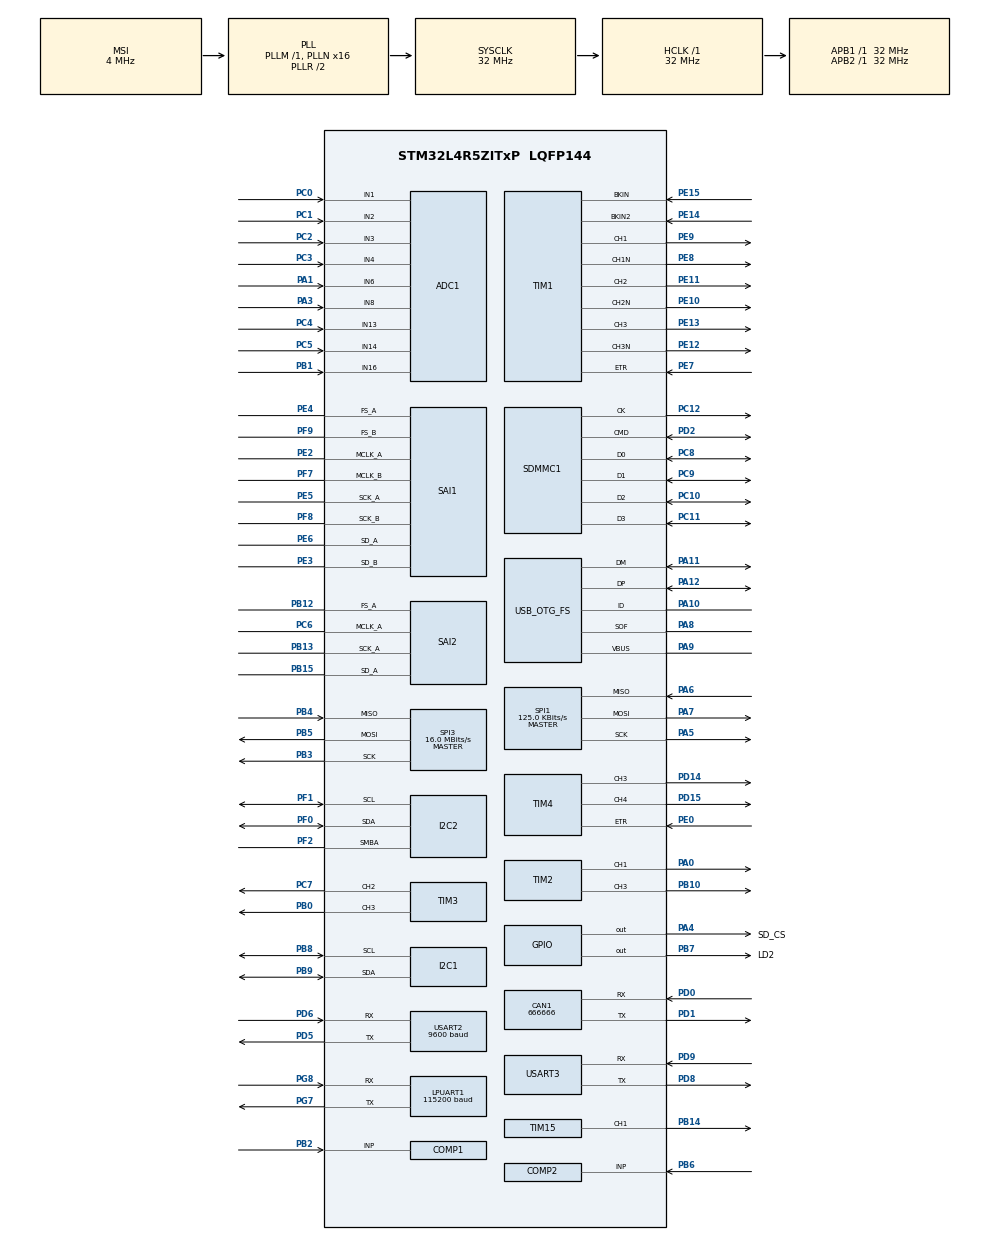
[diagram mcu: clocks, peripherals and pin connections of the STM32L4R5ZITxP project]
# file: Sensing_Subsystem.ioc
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ADC1.Channel-0\#ChannelRegularConversion=ADC_CHANNEL_1
ADC1.NbrOfConversionFlag=1
ADC1.OffsetNumber-0\#ChannelRegularConversion=ADC_OFFSET_NONE
ADC1.Rank-0\#ChannelRegularConversion=1
ADC1.SamplingTime-0\#ChannelRegularConversion=ADC_SAMPLETIME_2CYCLES_5
ADC1.master=1
CAN1.BS1=CAN_BS1_1TQ
CAN1.BS2=CAN_BS2_1TQ
CAN1.CalculateBaudRate=666666
CAN1.CalculateTimeBit=1500
CAN1.CalculateTimeQuantum=500.0
FATFS._USE_LFN=1
I2C1.Timing=0x00B07CB4
I2C2.Timeout=0x00008186
I2C2.Timing=0x00B07CB4
LPUART1.BaudRate=115200
LPUART1.WordLength=UART_WORDLENGTH_8B
Mcu.Family=STM32L4
Mcu.Name=STM32L4R5ZITxP
Mcu.Package=LQFP144
NVIC.LPUART1_IRQn=true\:0\:0\:false\:false\:true\:true\:true\:true
NVIC.PriorityGroup=NVIC_PRIORITYGROUP_4
NVIC.USART2_IRQn=true\:0\:0\:false\:false\:true\:true\:true\:true
PA0.Signal=S_TIM2_CH1
PA1.Signal=ADCx_IN6
PA10.Mode=OTG/Dual_Role_Device
PA10.Signal=USB_OTG_FS_ID
PA11.Mode=OTG/Dual_Role_Device
PA11.Signal=USB_OTG_FS_DM
PA12.Mode=OTG/Dual_Role_Device
PA12.Signal=USB_OTG_FS_DP
PA13\ (JTMS/SWDIO).Mode=Serial_Wire
PA13\ (JTMS/SWDIO).Signal=SYS_JTMS-SWDIO
PA14\ (JTCK/SWCLK).Mode=Serial_Wire
PA14\ (JTCK/SWCLK).Signal=SYS_JTCK-SWCLK
PA3.Signal=ADCx_IN8
PA4.GPIO_Label=SD_CS
PA4.GPIO_Speed=GPIO_SPEED_FREQ_VERY_HIGH
PA4.PinState=GPIO_PIN_SET
PA4.Signal=GPIO_Output
PA5.Mode=Full_Duplex_Master
PA5.Signal=SPI1_SCK
PA6.Mode=Full_Duplex_Master
PA6.Signal=SPI1_MISO
PA7.Mode=Full_Duplex_Master
PA7.Signal=SPI1_MOSI
PA8.Mode=Activate_SOF_FS
PA8.Signal=USB_OTG_FS_SOF
PA9.Mode=Activate_VBUS
PA9.Signal=USB_OTG_FS_VBUS
PB0.Signal=S_TIM3_CH3
PB1.Signal=ADCx_IN16
PB10.Signal=S_TIM2_CH3
PB12.Mode=SAI_A_MasterWithClock
PB12.Signal=SAI2_FS_A
PB13.Mode=SAI_A_MasterWithClock
PB13.Signal=SAI2_SCK_A
PB14.Signal=S_TIM15_CH1
PB15.Mode=SAI_A_MasterWithClock
PB15.Signal=SAI2_SD_A
PB2.Mode=INP
PB2.Signal=COMP1_INP
PB3\ (JTDO/TRACESWO).Mode=Full_Duplex_Master
PB3\ (JTDO/TRACESWO).Signal=SPI3_SCK
PB4\ (NJTRST).Mode=Full_Duplex_Master
PB4\ (NJTRST).Signal=SPI3_MISO
PB5.Mode=Full_Duplex_Master
PB5.Signal=SPI3_MOSI
PB6.Mode=INP
PB6.Signal=COMP2_INP
PB7.GPIO_Label=LD2
PB7.Signal=GPIO_Output
PB8.GPIO_Pu=GPIO_PULLUP
PB8.Mode=I2C
PB8.Signal=I2C1_SCL
PB9.GPIO_Pu=GPIO_PULLUP
PB9.Mode=I2C
PB9.Signal=I2C1_SDA
PC0.Signal=ADCx_IN1
PC1.Signal=ADCx_IN2
PC10.Mode=SD_4_bits_Wide_bus
PC10.Signal=SDMMC1_D2
PC11.Mode=SD_4_bits_Wide_bus
PC11.Signal=SDMMC1_D3
PC12.Mode=SD_4_bits_Wide_bus
PC12.Signal=SDMMC1_CK
PC13.Mode=SYS_WakeUp1
PC13.Signal=SYS_WKUP2
PC14-OSC32_IN\ (PC14).Mode=LSE-External-Oscillator
PC14-OSC32_IN\ (PC14).Signal=RCC_OSC32_IN
PC15-OSC32_OUT\ (PC15).Mode=LSE-External-Oscillator
PC15-OSC32_OUT\ (PC15).Signal=RCC_OSC32_OUT
PC2.Signal=ADCx_IN3
PC3.Signal=ADCx_IN4
PC4.Signal=ADCx_IN13
PC5.Signal=ADCx_IN14
PC6.Mode=SAI_A_MasterWithClock
PC6.Signal=SAI2_MCLK_A
PC7.Signal=S_TIM3_CH2
PC8.Mode=SD_4_bits_Wide_bus
PC8.Signal=SDMMC1_D0
PC9.Mode=SD_4_bits_Wide_bus
PC9.Signal=SDMMC1_D1
PD0.Mode=CAN_Activate
PD0.Signal=CAN1_RX
PD1.Mode=CAN_Activate
PD1.Signal=CAN1_TX
PD14.Signal=S_TIM4_CH3
PD15.Signal=S_TIM4_CH4
PD2.Mode=SD_4_bits_Wide_bus
PD2.Signal=SDMMC1_CMD
PD3.Signal=USART2_CTS
PD4.Signal=USART2_RTS
PD5.Mode=Asynchronous
PD5.Signal=USART2_TX
PD6.Mode=Asynchronous
PD6.Signal=USART2_RX
PD8.Mode=Asynchronous
PD8.Signal=USART3_TX
PD9.Mode=Asynchronous
PD9.Signal=USART3_RX
PE0.Signal=S_TIM4_ETR
PE10.Mode=PWM Generation2 CH2 CH2N
PE10.Signal=TIM1_CH2N
PE11.Signal=S_TIM1_CH2
PE12.Mode=PWM Generation3 CH3 CH3N
PE12.Signal=TIM1_CH3N
PE13.Signal=S_TIM1_CH3
PE14.Mode=Activate-Break-Input-2
PE14.Signal=TIM1_BKIN2
PE15.Mode=Activate-Break-Input
PE15.Signal=TIM1_BKIN
PE2.Mode=SAI_A_MasterWithClock
PE2.Signal=SAI1_MCLK_A
PE3.Mode=SAI_B_MasterWithClock
PE3.Signal=SAI1_SD_B
PE4.Mode=SAI_A_MasterWithClock
PE4.Signal=SAI1_FS_A
PE5.Mode=SAI_A_MasterWithClock
PE5.Signal=SAI1_SCK_A
PE6.Mode=SAI_A_MasterWithClock
PE6.Signal=SAI1_SD_A
PE7.Signal=S_TIM1_ETR
PE8.Mode=PWM Generation1 CH1 CH1N
PE8.Signal=TIM1_CH1N
PE9.Signal=S_TIM1_CH1
PF0.GPIO_Pu=GPIO_PULLUP
PF0.Mode=SMBus-Alert-mode
PF0.Signal=I2C2_SDA
PF1.GPIO_Pu=GPIO_PULLUP
PF1.Mode=SMBus-Alert-mode
PF1.Signal=I2C2_SCL
PF2.GPIO_Pu=GPIO_PULLUP
PF2.Mode=SMBus-Alert-mode
PF2.Signal=I2C2_SMBA
PF7.Mode=SAI_B_MasterWithClock
PF7.Signal=SAI1_MCLK_B
PF8.Mode=SAI_B_MasterWithClock
PF8.Signal=SAI1_SCK_B
PF9.Mode=SAI_B_MasterWithClock
PF9.Signal=SAI1_FS_B
PG7.Mode=Asynchronous
PG7.Signal=LPUART1_TX
PG8.Mode=Asynchronous
PG8.Signal=LPUART1_RX
PH0-OSC_IN\ (PH0).Mode=HSE-External-Oscillator
PH0-OSC_IN\ (PH0).Signal=RCC_OSC_IN
PH1-OSC_OUT\ (PH1).Mode=HSE-External-Oscillator
PH1-OSC_OUT\ (PH1).Signal=RCC_OSC_OUT
ProjectManager.HeapSize=0x200
ProjectManager.StackSize=0x400
ProjectManager.TargetToolchain=STM32CubeIDE
RCC.ADCFreq_Value=48000000
RCC.AHBFreq_Value=32000000
RCC.APB1Freq_Value=32000000
RCC.APB1TimFreq_Value=32000000
RCC.APB2Freq_Value=32000000
RCC.APB2TimFreq_Value=32000000
RCC.CortexFreq_Value=32000000
RCC.HCLKFreq_Value=32000000
RCC.HSE_VALUE=8000000
RCC.HSI48_VALUE=48000000
RCC.HSI_VALUE=16000000
RCC.MSI_VALUE=4000000
RCC.PLLN=16
RCC.PLLSAI1N=24
RCC.SYSCLKFreq_VALUE=32000000
RCC.SYSCLKSource=RCC_SYSCLKSOURCE_PLLCLK
RCC.USBFreq_Value=48000000
RCC.VCOOutputFreq_Value=64000000
SAI1.InitProtocol-SAI_A_MasterWithClock=Enable
SAI1.Instance-SAI_A_MasterWithClock=SAI$Index_Block_A
SAI1.Instance-SAI_B_MasterWithClock=SAI$Index_Block_B
SAI1.MClockEnable-SAI_A_MasterWithClock=SAI_MASTERCLOCK_ENABLE
SAI1.MClockEnable-SAI_B_MasterWithClock=SAI_MASTERCLOCK_ENABLE
SAI1.Synchro-SAI_A_MasterWithClock=SAI_ASYNCHRONOUS
SAI1.Synchro-SAI_B_MasterWithClock=SAI_ASYNCHRONOUS
SAI1.VirtualMode-SAI_A_MasterWithClock=VM_MASTER
SAI1.VirtualMode-SAI_B_MasterWithClock=VM_MASTER
SAI1.VirtualProtocol-SAI_A_BASIC=VM_BASIC_PROTOCOL
SAI2.Instance-SAI_A_MasterWithClock=SAI$Index_Block_A
SAI2.MClockEnable-SAI_A_MasterWithClock=SAI_MASTERCLOCK_ENABLE
SAI2.Synchro-SAI_A_MasterWithClock=SAI_ASYNCHRONOUS
SAI2.VirtualMode-SAI_A_MasterWithClock=VM_MASTER
SH.ADCx_IN1.0=ADC1_IN1,IN1-Single-Ended
SH.ADCx_IN13.0=ADC1_IN13,IN13-Single-Ended
SH.ADCx_IN14.0=ADC1_IN14,IN14-Single-Ended
SH.ADCx_IN16.0=ADC1_IN16,IN16-Single-Ended
SH.ADCx_IN2.0=ADC1_IN2,IN2-Single-Ended
SH.ADCx_IN3.0=ADC1_IN3,IN3-Single-Ended
SH.ADCx_IN4.0=ADC1_IN4,IN4-Single-Ended
SH.ADCx_IN6.0=ADC1_IN6,IN6-Single-Ended
SH.ADCx_IN8.0=ADC1_IN8,IN8-Single-Ended
SH.S_TIM15_CH1.0=TIM15_CH1,PWM Generation1 CH1
SH.S_TIM1_CH1.0=TIM1_CH1,PWM Generation1 CH1 CH1N
SH.S_TIM1_CH2.0=TIM1_CH2,PWM Generation2 CH2 CH2N
SH.S_TIM1_CH3.0=TIM1_CH3,PWM Generation3 CH3 CH3N
SH.S_TIM1_ETR.0=TIM1_ETR,ETR-as-clearing-source
SH.S_TIM2_CH1.0=TIM2_CH1,PWM Generation1 CH1
SH.S_TIM2_CH3.0=TIM2_CH3,PWM Generation3 CH3
SH.S_TIM3_CH2.0=TIM3_CH2,PWM Generation2 CH2
SH.S_TIM3_CH3.0=TIM3_CH3,PWM Generation3 CH3
SH.S_TIM4_CH3.0=TIM4_CH3,PWM Generation3 CH3
SH.S_TIM4_CH4.0=TIM4_CH4,PWM Generation4 CH4
SH.S_TIM4_ETR.0=TIM4_ETR,ETR-as-clearing-source
SPI1.BaudRatePrescaler=SPI_BAUDRATEPRESCALER_256
SPI1.CalculateBaudRate=125.0 KBits/s
SPI1.DataSize=SPI_DATASIZE_8BIT
SPI1.Direction=SPI_DIRECTION_2LINES
SPI1.Mode=SPI_MODE_MASTER
SPI1.VirtualType=VM_MASTER
SPI3.CalculateBaudRate=16.0 MBits/s
SPI3.Direction=SPI_DIRECTION_2LINES
SPI3.Mode=SPI_MODE_MASTER
SPI3.VirtualType=VM_MASTER
TIM1.Channel-PWM\ Generation1\ CH1\ CH1N=TIM_CHANNEL_1
TIM1.Channel-PWM\ Generation2\ CH2\ CH2N=TIM_CHANNEL_2
TIM1.Channel-PWM\ Generation3\ CH3\ CH3N=TIM_CHANNEL_3
TIM15.Channel-PWM\ Generation1\ CH1=TIM_CHANNEL_1
TIM2.Channel-PWM\ Generation1\ CH1=TIM_CHANNEL_1
TIM2.Channel-PWM\ Generation3\ CH3=TIM_CHANNEL_3
TIM3.Channel-PWM\ Generation2\ CH2=TIM_CHANNEL_2
TIM3.Channel-PWM\ Generation3\ CH3=TIM_CHANNEL_3
TIM4.Channel-PWM\ Generation3\ CH3=TIM_CHANNEL_3
TIM4.Channel-PWM\ Generation4\ CH4=TIM_CHANNEL_4
USART2.BaudRate=9600
USART2.VirtualMode-Asynchronous=VM_ASYNC
USART3.VirtualMode-Asynchronous=VM_ASYNC
VP_COMP1_VS_VREFINT.Mode=VREFINT
VP_FATFS_VS_Generic.Mode=User_defined
VP_SAI1_VP_$IpInstance_SAIA_SAI_BASIC.Mode=SAI_A_BASIC
board=NUCLEO-L4R5ZI-P

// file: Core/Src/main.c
/* USER CODE BEGIN Header */
/**
  ******************************************************************************
  * @file          : main.c
  * @brief         : Main program body - IMU + GPS + SD Card Integration
  * PROJECT        : EEE4113F Group 23 — Wave Direction, 2026
  * Author         : Batsirai Chris Rwatirera
  * BOARD          : STM32 NUCLEO-L4R5ZI-P
  ******************************************************************************
  */
/* USER CODE END Header */
#include "main.h"
#include "adc.h"
#include "can.h"
#include "comp.h"
#include "fatfs.h"
#include "i2c.h"
#include "usart.h"
#include "sai.h"
#include "sdmmc.h"
#include "spi.h"
#include "tim.h"
#include "usb_otg.h"
#include "gpio.h"

/* USER CODE BEGIN Includes */
#include <string.h>
#include <stdio.h>
#include "imu.h"
#include "gps.h"
#include "storage.h"  /* �? NEW: SD card module */
/* USER CODE END Includes */

/* USER CODE BEGIN PV */
extern UART_HandleTypeDef hlpuart1;
extern UART_HandleTypeDef huart2;
extern I2C_HandleTypeDef hi2c1;
/* USER CODE END PV */

void SystemClock_Config(void);
void PeriphCommonClock_Config(void);

/* USER CODE BEGIN 0 */

/* ═══════════════════════════════════════════════════════════════════════════
 * SD CARD SPI FUNCTIONS
 * ═══════════════════════════════════════════════════════════════════════════
 */

static uint8_t sd_spi_txrx(uint8_t data)
{
    uint8_t rx = 0xFF;
    HAL_SPI_TransmitReceive(&hspi1, &data, &rx, 1, HAL_MAX_DELAY);
    return rx;
}

static void sd_cs_high(void)
{
    HAL_GPIO_WritePin(GPIOA, GPIO_PIN_4, GPIO_PIN_SET);  // CS = PA4
    sd_spi_txrx(0xFF);
}

static void sd_cs_low(void)
{
    HAL_GPIO_WritePin(GPIOA, GPIO_PIN_4, GPIO_PIN_RESET);  // CS = PA4
    sd_spi_txrx(0xFF);
}

static void sd_send_dummy_clocks(void)
{
    sd_cs_high();
    for (int i = 0; i < 10; i++) {
        sd_spi_txrx(0xFF);
    }
}

static uint8_t sd_send_cmd(uint8_t cmd, uint32_t arg, uint8_t crc)
{
    uint8_t r1;

    sd_cs_low();

    sd_spi_txrx(0x40 | cmd);
    sd_spi_txrx((uint8_t)(arg >> 24));
    sd_spi_txrx((uint8_t)(arg >> 16));
    sd_spi_txrx((uint8_t)(arg >> 8));
    sd_spi_txrx((uint8_t)(arg));
    sd_spi_txrx(crc);

    for (int i = 0; i < 10; i++) {
        r1 = sd_spi_txrx(0xFF);
        if ((r1 & 0x80) == 0) {
            return r1;
        }
    }

    return 0xFF;
}

uint8_t sd_init(void)
{
    uint8_t r1;
    uint8_t r7[4];

    sd_send_dummy_clocks();

    r1 = sd_send_cmd(0, 0x00000000, 0x95);
    sd_cs_high();
    if (r1 != 0x01) return 1;

    r1 = sd_send_cmd(8, 0x000001AA, 0x87);
    r7[0] = sd_spi_txrx(0xFF);
    r7[1] = sd_spi_txrx(0xFF);
    r7[2] = sd_spi_txrx(0xFF);
    r7[3] = sd_spi_txrx(0xFF);
    sd_cs_high();

    if (r1 != 0x01 || r7[2] != 0x01 || r7[3] != 0xAA) return 2;

    uint32_t timeout = 0;
    do {
        r1 = sd_send_cmd(55, 0x00000000, 0xFF);
        sd_cs_high();
        r1 = sd_send_cmd(41, 0x40000000, 0xFF);
        sd_cs_high();
        timeout++;
        HAL_Delay(10);
    } while ((r1 != 0x00) && (timeout < 500));

    if (r1 != 0x00) return 3;

    r1 = sd_send_cmd(58, 0x00000000, 0xFF);
    sd_spi_txrx(0xFF);
    sd_spi_txrx(0xFF);
    sd_spi_txrx(0xFF);
    sd_spi_txrx(0xFF);
    sd_cs_high();

    if (r1 != 0x00) return 4;

    return 0;
}

uint8_t sd_read_block(uint32_t block_addr, uint8_t *buffer)
{
    uint8_t r1;
    uint8_t token;

    r1 = sd_send_cmd(17, block_addr, 0xFF);
    if (r1 != 0x00) {
        sd_cs_high();
        return r1;
    }

    for (uint32_t i = 0; i < 100000; i++) {
        token = sd_spi_txrx(0xFF);
        if (token == 0xFE) break;
    }

    if (token != 0xFE) {
        sd_cs_high();
        return 0xFE;
    }

    for (uint32_t i = 0; i < 512; i++) {
        buffer[i] = sd_spi_txrx(0xFF);
    }

    sd_spi_txrx(0xFF);
    sd_spi_txrx(0xFF);

    sd_cs_high();
    return 0x00;
}

uint8_t sd_write_block(uint32_t block_addr, const uint8_t *data)
{
    uint8_t r1;
    uint8_t resp;
    uint8_t dummy;

    r1 = sd_send_cmd(24, block_addr, 0xFF);
    if (r1 != 0x00) {
        sd_cs_high();
        return r1;
    }

    sd_spi_txrx(0xFF);
    sd_spi_txrx(0xFE);

    for (uint32_t i = 0; i < 512; i++) {
        sd_spi_txrx(data[i]);
    }

    sd_spi_txrx(0xFF);
    sd_spi_txrx(0xFF);

    resp = sd_spi_txrx(0xFF);

    if ((resp & 0x1F) != 0x05) {
        sd_cs_high();
        return resp;
    }

    uint32_t timeout = 1000000;
    do {
        dummy = sd_spi_txrx(0xFF);
        timeout--;
    } while ((dummy != 0xFF) && (timeout > 0));

    sd_cs_high();

    return (timeout == 0) ? 0xFE : 0x00;
}

/* USER CODE END 0 */

int main(void)
{

  /* USER CODE BEGIN 1 */
  /* Enable FPU before HAL_Init() */
  SCB->CPACR |= ((3UL << 10*2)|(3UL << 11*2));
  /* USER CODE END 1 */

  /* MCU Configuration--------------------------------------------------------*/

  /* Reset of all peripherals, Initializes the Flash interface and the Systick. */
  HAL_Init();

  /* USER CODE BEGIN Init */

  // LED setup via direct register access
  RCC->AHB2ENR |= RCC_AHB2ENR_GPIOBEN;  // Enable GPIOB clock
  RCC->AHB2ENR |= RCC_AHB2ENR_GPIOCEN;  // Enable GPIOC clock

  // Configure PB7 (Blue LED), PB14 (Red LED) as outputs
  GPIOB->MODER &= ~(3UL << (7*2));
  GPIOB->MODER |= (1UL << (7*2));
  GPIOB->MODER &= ~(3UL << (14*2));
  GPIOB->MODER |= (1UL << (14*2));

  // Configure PC7 (Green LED) as output
  GPIOC->MODER &= ~(3UL << (7*2));
  GPIOC->MODER |= (1UL << (7*2));

  /* USER CODE END Init */

  /* Configure the system clock */
  SystemClock_Config();

  /* Configure the peripherals common clocks */
  PeriphCommonClock_Config();

  /* USER CODE BEGIN SysInit */

    // Initialize peripherals
    MX_GPIO_Init();
    MX_LPUART1_UART_Init();
    MX_USART2_UART_Init();
    MX_I2C1_Init();
    MX_SPI1_Init();       /* �? NEW: SPI for SD card */
    MX_FATFS_Init();      /* �? NEW: FatFs middleware */

    // Helper function to print messages
    void print_msg(const char* msg) {
      HAL_UART_Transmit(&hlpuart1, (uint8_t*)msg, strlen(msg), 1000);
    }

    // Print startup banner
    print_msg("\r\n========================================\r\n");
    print_msg("  EEE4113F Group 23 — Wave Direction\r\n");
    print_msg("  IMU + GPS + SD Card Integration\r\n");
    print_msg("=========================================\r\n");

    char cfg[300];
    snprintf(cfg, sizeof(cfg),
        "  IMU rate    : %d Hz\r\n"
        "  GPS rate    : %d Hz\r\n"
        "  Session     : %d min  (%lu IMU samples)\r\n"
        "  Interval    : %d hours\r\n"
        "  IMU batch   : every %d samples (1s)\r\n"
        "  GPS batch   : every %d samples (10s)\r\n"
        "  SD card     : SPI mode, power-loss safe\r\n"
        "=========================================\r\n",
        IMU_SAMPLE_RATE_HZ,
        GPS_SAMPLE_RATE_HZ,
        IMU_SESSION_DURATION_MIN,
        (unsigned long)IMU_SAMPLES_PER_SESSION,
        IMU_SESSION_INTERVAL_HOURS,
        IMU_BATCH_SIZE,
        GPS_BATCH_SIZE);
    print_msg(cfg);

    /* ── ONE-TIME STARTUP INITIALISATION ───────────────────────────────── */

    // Initialize IMU module
    print_msg("[MAIN] Initialising IMU...\r\n");
    if (!IMU_Init())
    {
        print_msg("[MAIN] IMU init FAILED. Halting.\r\n");
        while(1) {
          GPIOB->BSRR = GPIO_PIN_14;  // Red LED blink = error
          HAL_Delay(200);
          GPIOB->BSRR = GPIO_PIN_14 << 16;
          HAL_Delay(200);
        }
    }

    // Calibrate IMU (sensor must be still and flat for 5 seconds)
    print_msg("[MAIN] Calibrating IMU (5 sec - keep still)...\r\n");
    if (!IMU_Calibrate())
    {
        print_msg("[MAIN] IMU calibration FAILED. Halting.\r\n");
        while(1) {
          GPIOB->BSRR = GPIO_PIN_14;  // Red LED blink = error
          HAL_Delay(200);
          GPIOB->BSRR = GPIO_PIN_14 << 16;
          HAL_Delay(200);
        }
    }

    // Initialize GPS module
    print_msg("[MAIN] Initialising GPS...\r\n");
    if (!GPS_Init())
    {
        print_msg("[MAIN] GPS init FAILED. Continuing without GPS.\r\n");
        /* Note: GPS hardware issue known - continue with IMU-only logging */
    }

    // ★ NEW: Initialize SD card ★
    print_msg("[MAIN] Initialising SD card...\r\n");
    if (!Storage_Init())
    {
        print_msg("[MAIN] SD card init FAILED. Halting.\r\n");
        print_msg("[MAIN] Check: Card inserted? FAT32 formatted? SPI wiring?\r\n");
        while(1) {
          GPIOB->BSRR = GPIO_PIN_14;  // Red LED blink = error
          HAL_Delay(300);
          GPIOB->BSRR = GPIO_PIN_14 << 16;
          HAL_Delay(300);
        }
    }

    print_msg("[MAIN] All modules ready. Starting session loop.\r\n\r\n");

    GPIOC->BSRR = GPIO_PIN_7;  // Green LED ON = initialization complete

    /* ── DAILY SESSION LOOP ──────────────────────────────────────────── */

    uint16_t session_number = 0;

    while(1)
    {
      /* ── START SESSION ───────────────────────────────────────────────── */
      session_number++;
      char sess_msg[120];
      snprintf(sess_msg, sizeof(sess_msg),
          "[MAIN] Session %u starting (30 min: IMU @ %d Hz, GPS @ %d Hz)\r\n",
          session_number, IMU_SAMPLE_RATE_HZ, GPS_SAMPLE_RATE_HZ);
      print_msg(sess_msg);

      IMU_Wake();
      GPS_Wake();

      // ★ NEW: Open session files on SD card ★
      if (!Storage_OpenSession(session_number))
      {
          print_msg("[MAIN] ERROR: Could not open SD session. Halting.\r\n");
          while(1) {
            GPIOB->BSRR = GPIO_PIN_14;  // Red LED blink = error
            HAL_Delay(500);
            GPIOB->BSRR = GPIO_PIN_14 << 16;
            HAL_Delay(500);
          }
      }

      /* ── RECORD FOR 30 MINUTES ──────────────────────────────────────── */
      uint32_t session_start = HAL_GetTick();
      uint32_t imu_samples_written = 0;
      uint32_t gps_samples_written = 0;

      while (HAL_GetTick() - session_start < IMU_SESSION_MS)
      {
          GPIOB->BSRR = GPIO_PIN_7;  // Blue LED ON during sampling

          // Non-blocking ticks for both sensors
          IMU_Tick();
          GPS_Tick();

          // ★ Check if IMU batch is ready (every 100 samples = 1 second) ★
          if (imu_batch_ready)
          {
              // Write to SD card (includes f_sync for power-loss safety)
              if (!Storage_WriteIMUBatch(imu_batch, imu_batch_count))
              {
                  print_msg("[MAIN] ERROR: IMU write failed!\r\n");
                  /* Could halt here, or continue logging */
              }

              imu_samples_written += imu_batch_count;
              IMU_ClearBatch();

              GPIOB->BSRR = GPIO_PIN_7 << 16;  // Blue LED OFF after write
          }

          // ★ Check if GPS batch is ready (every 80 samples = 10 seconds) ★
          if (gps_batch_ready)
          {
              // Write to SD card (includes f_sync for power-loss safety)
              if (!Storage_WriteGPSBatch(gps_batch, gps_batch_count))
              {
                  print_msg("[MAIN] ERROR: GPS write failed!\r\n");
                  /* Could halt here, or continue logging */
              }

              gps_samples_written += gps_batch_count;
              GPS_ClearBatch();
          }
      }

      /* ── END SESSION ──────────────────────────────────────────────────── */
      char end_msg[120];
      snprintf(end_msg, sizeof(end_msg),
          "[MAIN] Session %u complete.\r\n"
          "       IMU: %lu samples | GPS: %lu samples\r\n",
          session_number,
          (unsigned long)imu_samples_written,
          (unsigned long)gps_samples_written);
      print_msg(end_msg);

      IMU_Sleep();
      GPS_Sleep();

      // ★ NEW: Close session files (final sync happens here) ★
      Storage_CloseSession();

      /* ── WAIT 23.5 HOURS UNTIL NEXT SESSION ────────────────────────── */
      uint32_t elapsed = HAL_GetTick() - session_start;
      uint32_t wait_time = 0;

      if (IMU_SESSION_INTERVAL_MS > elapsed)
      {
          wait_time = IMU_SESSION_INTERVAL_MS - elapsed;
      }

      char wait_msg[70];
      snprintf(wait_msg, sizeof(wait_msg),
          "[MAIN] Sleeping for %.1f hours until next session.\r\n\r\n",
          (float)wait_time / 3600000.0f);
      print_msg(wait_msg);

      HAL_Delay(wait_time);  // Wait remainder of 24 hours
    }

  /* USER CODE END SysInit */

  /* Initialize all configured peripherals */
  MX_GPIO_Init();
  MX_ADC1_Init();
  MX_CAN1_Init();
  MX_COMP1_Init();
  MX_COMP2_Init();
  MX_I2C1_Init();
  MX_I2C2_SMBUS_Init();
  MX_LPUART1_UART_Init();
  MX_USART2_UART_Init();
  MX_USART3_UART_Init();
  MX_SAI1_Init();
  MX_SAI2_Init();
  MX_SDMMC1_SD_Init();
  MX_SPI1_Init();
  MX_SPI3_Init();
  MX_TIM1_Init();
  MX_TIM2_Init();
  MX_TIM3_Init();
  MX_TIM4_Init();
  MX_TIM15_Init();
  MX_USB_OTG_FS_USB_Init();
  MX_FATFS_Init();
  /* USER CODE BEGIN 2 */

  // This code never runs because we're stuck in the while(1) above

  /* USER CODE END 2 */

  /* Infinite loop */
  while (1)
  {

  }
}

void SystemClock_Config(void)
{
  RCC_OscInitTypeDef RCC_OscInitStruct = {0};
  RCC_ClkInitTypeDef RCC_ClkInitStruct = {0};

  /** Configure the main internal regulator output voltage
  */
  if (HAL_PWREx_ControlVoltageScaling(PWR_REGULATOR_VOLTAGE_SCALE1) != HAL_OK)
  {
    Error_Handler();
  }

  /** Configure LSE Drive Capability
  */
  HAL_PWR_EnableBkUpAccess();
  __HAL_RCC_LSEDRIVE_CONFIG(RCC_LSEDRIVE_LOW);

  /** Initializes the RCC Oscillators according to the specified parameters
  * in the RCC_OscInitTypeDef structure.
  */
  RCC_OscInitStruct.OscillatorType = RCC_OSCILLATORTYPE_LSE|RCC_OSCILLATORTYPE_MSI;
  RCC_OscInitStruct.LSEState = RCC_LSE_ON;
  RCC_OscInitStruct.MSIState = RCC_MSI_ON;
  RCC_OscInitStruct.MSICalibrationValue = 0;
  RCC_OscInitStruct.MSIClockRange = RCC_MSIRANGE_6;
  RCC_OscInitStruct.PLL.PLLState = RCC_PLL_ON;
  RCC_OscInitStruct.PLL.PLLSource = RCC_PLLSOURCE_MSI;
  RCC_OscInitStruct.PLL.PLLM = 1;
  RCC_OscInitStruct.PLL.PLLN = 16;
  RCC_OscInitStruct.PLL.PLLP = RCC_PLLP_DIV2;
  RCC_OscInitStruct.PLL.PLLQ = RCC_PLLQ_DIV2;
  RCC_OscInitStruct.PLL.PLLR = RCC_PLLR_DIV2;
  if (HAL_RCC_OscConfig(&RCC_OscInitStruct) != HAL_OK)
  {
    Error_Handler();
  }

  /** Initializes the CPU, AHB and APB buses clocks
  */
  RCC_ClkInitStruct.ClockType = RCC_CLOCKTYPE_HCLK|RCC_CLOCKTYPE_SYSCLK
                              |RCC_CLOCKTYPE_PCLK1|RCC_CLOCKTYPE_PCLK2;
  RCC_ClkInitStruct.SYSCLKSource = RCC_SYSCLKSOURCE_PLLCLK;
  RCC_ClkInitStruct.AHBCLKDivider = RCC_SYSCLK_DIV1;
  RCC_ClkInitStruct.APB1CLKDivider = RCC_HCLK_DIV1;
  RCC_ClkInitStruct.APB2CLKDivider = RCC_HCLK_DIV1;

  if (HAL_RCC_ClockConfig(&RCC_ClkInitStruct, FLASH_LATENCY_1) != HAL_OK)
  {
    Error_Handler();
  }

  /** Enable MSI Auto calibration
  */
  HAL_RCCEx_EnableMSIPLLMode();
}

void PeriphCommonClock_Config(void)
{
  RCC_PeriphCLKInitTypeDef PeriphClkInit = {0};

  /** Initializes the peripherals clock
  */
  PeriphClkInit.PeriphClockSelection = RCC_PERIPHCLK_SAI1|RCC_PERIPHCLK_SAI2
                              |RCC_PERIPHCLK_USB|RCC_PERIPHCLK_ADC;
  PeriphClkInit.Sai1ClockSelection = RCC_SAI1CLKSOURCE_PLLSAI1;
  PeriphClkInit.Sai2ClockSelection = RCC_SAI2CLKSOURCE_PLLSAI1;
  PeriphClkInit.AdcClockSelection = RCC_ADCCLKSOURCE_PLLSAI1;
  PeriphClkInit.UsbClockSelection = RCC_USBCLKSOURCE_PLLSAI1;
  PeriphClkInit.PLLSAI1.PLLSAI1Source = RCC_PLLSOURCE_MSI;
  PeriphClkInit.PLLSAI1.PLLSAI1M = 1;
  PeriphClkInit.PLLSAI1.PLLSAI1N = 24;
  PeriphClkInit.PLLSAI1.PLLSAI1P = RCC_PLLP_DIV2;
  PeriphClkInit.PLLSAI1.PLLSAI1Q = RCC_PLLQ_DIV2;
  PeriphClkInit.PLLSAI1.PLLSAI1R = RCC_PLLR_DIV2;
  PeriphClkInit.PLLSAI1.PLLSAI1ClockOut = RCC_PLLSAI1_SAI1CLK|RCC_PLLSAI1_48M2CLK
                              |RCC_PLLSAI1_ADC1CLK;
  if (HAL_RCCEx_PeriphCLKConfig(&PeriphClkInit) != HAL_OK)
  {
    Error_Handler();
  }
}

void Error_Handler(void)
{
  /* USER CODE BEGIN Error_Handler_Debug */
  __disable_irq();
  while (1)
  {
    GPIOB->BSRR = GPIO_PIN_7;  // Blue LED blink fast = error
    for(volatile uint32_t i=0; i<300000; i++);
    GPIOB->BSRR = GPIO_PIN_7 << 16;
    for(volatile uint32_t i=0; i<300000; i++);
  }
  /* USER CODE END Error_Handler_Debug */
}
